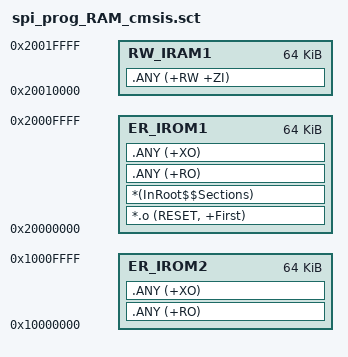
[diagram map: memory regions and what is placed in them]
; *************************************************************
; *** Scatter-Loading Description File generated by uVision ***
; *************************************************************

LR_IROM1 0x20000000 0x00010000  {    ; load region size_region
  ER_IROM1 0x20000000 0x00010000  {  ; load address = execution address
   *.o (RESET, +First)
   *(InRoot$$Sections)
   .ANY (+RO)
   .ANY (+XO)
  }
  
  RW_IRAM1 0x20010000 0x00010000  {  ; RW data
   .ANY (+RW +ZI)
  }
}

LR_IROM2 0x10000000 0x00010000  {    ; load region size_region
  ER_IROM2 0x10000000 0x00010000  {  ; load address = execution address
   .ANY (+RO)
   .ANY (+XO)
  }
}
